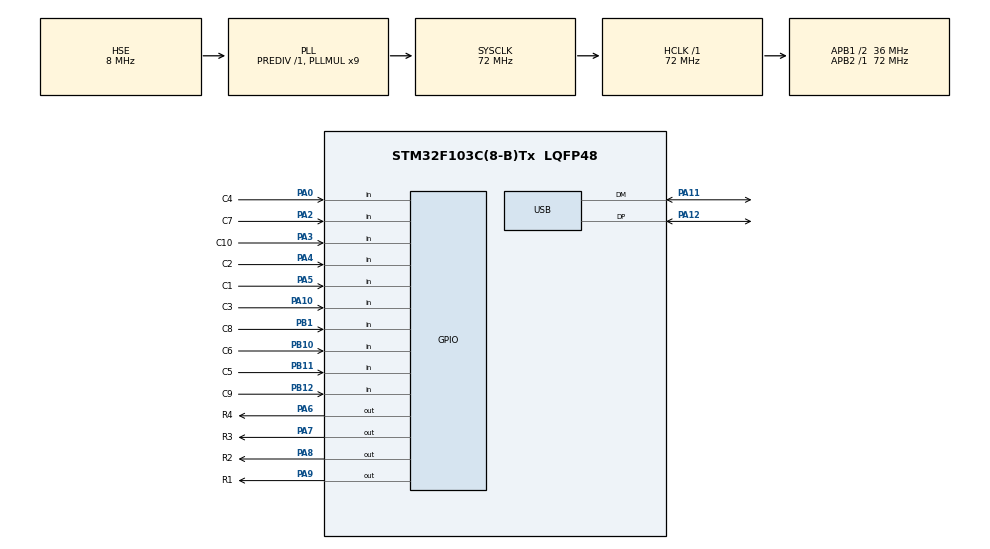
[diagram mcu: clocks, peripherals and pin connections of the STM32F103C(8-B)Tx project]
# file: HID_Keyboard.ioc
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Mcu.Family=STM32F1
Mcu.Name=STM32F103C(8-B)Tx
Mcu.Package=LQFP48
NVIC.PriorityGroup=NVIC_PRIORITYGROUP_4
NVIC.USB_LP_CAN1_RX0_IRQn=true\:0\:0\:false\:false\:true\:false\:true\:true
PA0-WKUP.GPIO_Label=C4
PA0-WKUP.GPIO_PuPd=GPIO_PULLUP
PA0-WKUP.Signal=GPIO_Input
PA10.GPIO_Label=C3
PA10.GPIO_PuPd=GPIO_PULLUP
PA10.Signal=GPIO_Input
PA11.Mode=Device
PA11.Signal=USB_DM
PA12.Mode=Device
PA12.Signal=USB_DP
PA2.GPIO_Label=C7
PA2.GPIO_PuPd=GPIO_PULLUP
PA2.Signal=GPIO_Input
PA3.GPIO_Label=C10
PA3.GPIO_PuPd=GPIO_PULLUP
PA3.Signal=GPIO_Input
PA4.GPIO_Label=C2
PA4.GPIO_PuPd=GPIO_PULLUP
PA4.Signal=GPIO_Input
PA5.GPIO_Label=C1
PA5.GPIO_PuPd=GPIO_PULLUP
PA5.Signal=GPIO_Input
PA6.GPIO_Label=R4
PA6.Signal=GPIO_Output
PA7.GPIO_Label=R3
PA7.Signal=GPIO_Output
PA8.GPIO_Label=R2
PA8.Signal=GPIO_Output
PA9.GPIO_Label=R1
PA9.Signal=GPIO_Output
PB1.GPIO_Label=C8
PB1.GPIO_PuPd=GPIO_PULLUP
PB1.Signal=GPIO_Input
PB10.GPIO_Label=C6
PB10.GPIO_PuPd=GPIO_PULLUP
PB10.Signal=GPIO_Input
PB11.GPIO_Label=C5
PB11.GPIO_PuPd=GPIO_PULLUP
PB11.Signal=GPIO_Input
PB12.GPIO_Label=C9
PB12.GPIO_PuPd=GPIO_PULLUP
PB12.Signal=GPIO_Input
PD0-OSC_IN.Mode=HSE-External-Oscillator
PD0-OSC_IN.Signal=RCC_OSC_IN
PD1-OSC_OUT.Mode=HSE-External-Oscillator
PD1-OSC_OUT.Signal=RCC_OSC_OUT
ProjectManager.HeapSize=0x200
ProjectManager.StackSize=0x400
ProjectManager.TargetToolchain=STM32CubeIDE
RCC.AHBFreq_Value=72000000
RCC.APB1CLKDivider=RCC_HCLK_DIV2
RCC.APB1Freq_Value=36000000
RCC.APB1TimFreq_Value=72000000
RCC.APB2Freq_Value=72000000
RCC.APB2TimFreq_Value=72000000
RCC.HCLKFreq_Value=72000000
RCC.PLLMUL=RCC_PLL_MUL9
RCC.PLLSourceVirtual=RCC_PLLSOURCE_HSE
RCC.SYSCLKFreq_VALUE=72000000
RCC.SYSCLKSource=RCC_SYSCLKSOURCE_PLLCLK
RCC.USBFreq_Value=48000000
RCC.USBPrescaler=RCC_USBCLKSOURCE_PLL_DIV1_5
USB_DEVICE.CLASS_NAME_FS=HID
USB_DEVICE.PRODUCT_STRING_HID_FS=ASKB
USB_DEVICE.VirtualMode=Hid
USB_DEVICE.VirtualModeFS=Hid_FS
VP_SYS_VS_ND.Mode=No_Debug
VP_USB_DEVICE_VS_USB_DEVICE_HID_FS.Mode=HID_FS
board=custom

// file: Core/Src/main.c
/* USER CODE BEGIN Header */
/**
  ******************************************************************************
  * @file           : main.c
  * @brief          : Main program body
  ******************************************************************************
  * @attention
  *
  * Copyright (c) 2024 STMicroelectronics.
  * All rights reserved.
  *
  * This software is licensed under terms that can be found in the LICENSE file
  * in the root directory of this software component.
  * If no LICENSE file comes with this software, it is provided AS-IS.
  *
  ******************************************************************************
  */
/* USER CODE END Header */
#include "main.h"
#include "usb_device.h"
#include "usb_hid_keys.h"

/* USER CODE BEGIN Includes */
#include "usbd_hid.h"
/* USER CODE END Includes */

/* USER CODE BEGIN PV */
extern USBD_HandleTypeDef hUsbDeviceFS;

/* USER CODE END PV */

void SystemClock_Config(void);
static void MX_GPIO_Init(void);

int main(void)
{

  /* MCU Configuration--------------------------------------------------------*/

  /* Reset of all peripherals, Initializes the Flash interface and the Systick. */
  HAL_Init();

  /* Configure the system clock */
  SystemClock_Config();

  /* Initialize all configured peripherals */
  MX_GPIO_Init();
  MX_USB_DEVICE_Init();

  /* USER CODE BEGIN 2 */
	//Esta estructura es para manejar mas facilmente los pines
  	typedef struct {
  		uint16_t Pin;
  		GPIO_TypeDef* GPIO_Port;
	} stm32GPIO;

	//Estructura del reporte que se envia por protocolo HID a la computadora
  	typedef struct {
	    uint8_t MODIFIER;
      	uint8_t RESERVED;
      	uint8_t KEYCODE01;
      	uint8_t KEYCODE02;
      	uint8_t KEYCODE03;
      	uint8_t KEYCODE04;
      	uint8_t KEYCODE05;
      	uint8_t KEYCODE06;
	} keyboardReportsDes;

	//Inicializacion de la esttructura con los pins de las filas
	stm32GPIO GPIORows[4] = {
		{R1_Pin, R1_GPIO_Port},
		{R2_Pin, R2_GPIO_Port},
		{R3_Pin, R3_GPIO_Port},
		{R4_Pin, R4_GPIO_Port}
	};

	//Inicializacion de la esttructura con los pins de las columnas
	stm32GPIO GPIOCols[10] = {
		{C1_Pin, C1_GPIO_Port},
		{C2_Pin, C2_GPIO_Port},
		{C3_Pin, C3_GPIO_Port},
		{C4_Pin, C4_GPIO_Port},
		{C5_Pin, C5_GPIO_Port},
		{C6_Pin, C6_GPIO_Port},
		{C7_Pin, C7_GPIO_Port},
		{C8_Pin, C8_GPIO_Port},
		{C9_Pin, C9_GPIO_Port},
		{C10_Pin, C10_GPIO_Port}
	};

	//Inicializacion de la estructura con los pins repetidos para las estructuras de control
	stm32GPIO GPIOControl[3] = {
		{C8_Pin, C8_GPIO_Port},
		{C5_Pin, C5_GPIO_Port},
		{C7_Pin, C7_GPIO_Port}
	};

	uint8_t keyMatrix[5][10][3] =
		{
			{
				{
					Q,K1,F1
				},
				{
					W,K2,F2
				},
				{
					E,K3,F3
				},
				{
					R,K4,F4
				},
				{
					T,K5,VUP
				},
				{
					Y,K6,PREV
				},
				{
					U,K7,PLAY
				},
				{
					I,K8,NEXT
				},
				{
					O,K9,STOP
				},
				{
					P,K0,PRINT
				}
			},
			{
				{
					A,ESC,F5
				},
				{
					S,0,F6
				},
				{
					D,0,F7
				},
				{
					F,0,F8
				},
				{
					G,0,VDN
				},
				{
					H,LCORCH,FIZ
				},
				{
					J,RCORCH,FAB
				},
				{
					K,BSLASH,FAR
				},
				{
					L,GUION,FDE
				},
				{
					PYCOMA,IGUAL,BLOCKM
				}
			},
			{
				{
					Z,PUP,F9
				},
				{
					X,PDN,F10
				},
				{
					C,HOME,F11
				},
				{
					V,END,F12
				},
				{
					B,0,MUTE
				},
				{
					ENTER,ENTER,ENTER
				},
				{
					N,APPMENU,0
				},
				{
					M,BCOMILL,0
				},
				{
					COMA,COMILLA,0
				},
				{
					PUNTO,TAB,0x00
				}
			},
			{
				{
					0,0,0
				},
				{
					0,0,0
				},
				{
					0,0,0
				},
				{
					SPACE,SPACE,SPACE
				},
				{
					0,0,0
				},
				{
					0,0,0
				},
				{
					0,0,0
				},
				{
					0,0,0
				},
				{
					0,0,0
				},
				{
					SLASH,BACKS,DELETE
				}
			},
			{
				{
					SHIFT,SHIFT,SHIFT
				},
				{
					CTRL,CTRL,CTRL
				},
				{
					ALT,GUI,ALT
				},
			}
		};

	//Inicializacion de la estructura para el reporte HID
	keyboardReportsDes HIDKeyboard = {0,0,0,0,0,0,0,0};

	//Short que se utiliza para definir en que capa del teclado estamos parados
	short control = 0;

	//While loop que se ejecuta durante todo el funcionamiento del equipo
	while (1)
	{
		//Este es el puntero que utilizo para cargar los codigos dentro de la estructura de reporte de manera secuencial
		//solo se usa ara los KEYCODE*, los primeros dos bytes se manejan de manera distinta.
		uint8_t *ptr_key = &HIDKeyboard.KEYCODE01;

		//Coloco los pines en la posicion de inicio
		for(int i = 0 ; i < 4; i++)
		{
				HAL_GPIO_WritePin(GPIORows[i].GPIO_Port, GPIORows[i].Pin, GPIO_PIN_SET);
		}
		HAL_GPIO_WritePin(GPIORows[3].GPIO_Port, GPIORows[3].Pin, GPIO_PIN_RESET);

		//Defino la capa donde se esta trabajando segun los dos botones internos que no modifican directametne
		//el reporte de teclad (fnL y fnR)
		if(!(HAL_GPIO_ReadPin(C3_GPIO_Port, C3_Pin))){
			control = C1;
		}

		if (!(HAL_GPIO_ReadPin(C9_GPIO_Port, C9_Pin))){
			control = C2;
		}

		//Compruebo que botones estan siendo pulsados paca configurar los modificadores y las capas de teclado
		for(int i = 0; i < 3; i++)
		{
			if(!(HAL_GPIO_ReadPin(GPIOControl[i].GPIO_Port, GPIOControl[i].Pin)))
			{
				HIDKeyboard.MODIFIER = keyMatrix[4][i][control] + HIDKeyboard.MODIFIER;
			}
		}

		//for que recorre las filas
		for(int i = 0; i < 4; i++)
		{
			//Este segundo loop anidado se encarga de apagar la corriente de todos los pines que no se tengan que
			//leer durante este ciclo.
			for(int j = 0; j < 4; j++)
			{
				if(j == i)
				{
					HAL_GPIO_WritePin(GPIORows[j].GPIO_Port, GPIORows[j].Pin, GPIO_PIN_RESET);
				}
				else
				{
					HAL_GPIO_WritePin(GPIORows[j].GPIO_Port, GPIORows[j].Pin, GPIO_PIN_SET);
				}
			}

			//Ahora se realiza un segundo loop que se encarga de recorrer cada una de las columnas,
			//este se corre 10 veces por cada fila. Aparte, si se carga un byte dentro de la estructura
			//de reporte, mueve el puntero adelante hasta llegar al ultimo espacio de memoria, en ese caso
			//vuelve al principio
			for(int h = 0; h < 10; h++)
			{
				if(!(HAL_GPIO_ReadPin(GPIOCols[h].GPIO_Port, GPIOCols[h].Pin)))
				{
					*ptr_key = keyMatrix[i][h][control];

					if(keyMatrix[i][h][control] != 0x00)
					{
						if(ptr_key != &HIDKeyboard.KEYCODE06)
						{
							ptr_key++;
						}
						else
						{
							ptr_key = &HIDKeyboard.KEYCODE01;
						}
					}
				}
			}
		}

		//Envio el reporte por USB
		USBD_HID_SendReport(&hUsbDeviceFS,&HIDKeyboard,sizeof(HIDKeyboard));
		//Espero para que no se pisen los reportes dentro del cable
		HAL_Delay(25);
		//Limpio todas las variabes necesarias antes de que vuelva a arrancar el loop
		//principal de la aplicacion.
		HIDKeyboard.MODIFIER  = 0x00;
		HIDKeyboard.RESERVED  = 0x00;
		HIDKeyboard.KEYCODE01 = 0x00;
		HIDKeyboard.KEYCODE02 = 0x00;
		HIDKeyboard.KEYCODE03 = 0x00;
		HIDKeyboard.KEYCODE04 = 0x00;
		HIDKeyboard.KEYCODE05 = 0x00;
		HIDKeyboard.KEYCODE06 = 0x00;
		control = 0;

      /* USER CODE END 3 */

    /* USER CODE END 3 */
    }
}

void SystemClock_Config(void)
{
  RCC_OscInitTypeDef RCC_OscInitStruct = {0};
  RCC_ClkInitTypeDef RCC_ClkInitStruct = {0};
  RCC_PeriphCLKInitTypeDef PeriphClkInit = {0};

  /** Initializes the RCC Oscillators according to the specified parameters
  * in the RCC_OscInitTypeDef structure.
  */
  RCC_OscInitStruct.OscillatorType = RCC_OSCILLATORTYPE_HSE;
  RCC_OscInitStruct.HSEState = RCC_HSE_ON;
  RCC_OscInitStruct.HSEPredivValue = RCC_HSE_PREDIV_DIV1;
  RCC_OscInitStruct.HSIState = RCC_HSI_ON;
  RCC_OscInitStruct.PLL.PLLState = RCC_PLL_ON;
  RCC_OscInitStruct.PLL.PLLSource = RCC_PLLSOURCE_HSE;
  RCC_OscInitStruct.PLL.PLLMUL = RCC_PLL_MUL9;
  if (HAL_RCC_OscConfig(&RCC_OscInitStruct) != HAL_OK)
  {
    Error_Handler();
  }

  /** Initializes the CPU, AHB and APB buses clocks
  */
  RCC_ClkInitStruct.ClockType = RCC_CLOCKTYPE_HCLK|RCC_CLOCKTYPE_SYSCLK
                              |RCC_CLOCKTYPE_PCLK1|RCC_CLOCKTYPE_PCLK2;
  RCC_ClkInitStruct.SYSCLKSource = RCC_SYSCLKSOURCE_PLLCLK;
  RCC_ClkInitStruct.AHBCLKDivider = RCC_SYSCLK_DIV1;
  RCC_ClkInitStruct.APB1CLKDivider = RCC_HCLK_DIV2;
  RCC_ClkInitStruct.APB2CLKDivider = RCC_HCLK_DIV1;

  if (HAL_RCC_ClockConfig(&RCC_ClkInitStruct, FLASH_LATENCY_2) != HAL_OK)
  {
    Error_Handler();
  }
  PeriphClkInit.PeriphClockSelection = RCC_PERIPHCLK_USB;
  PeriphClkInit.UsbClockSelection = RCC_USBCLKSOURCE_PLL_DIV1_5;
  if (HAL_RCCEx_PeriphCLKConfig(&PeriphClkInit) != HAL_OK)
  {
    Error_Handler();
  }
}

static void MX_GPIO_Init(void)
{
  GPIO_InitTypeDef GPIO_InitStruct = {0};

  /* GPIO Ports Clock Enable */
  __HAL_RCC_GPIOD_CLK_ENABLE();
  __HAL_RCC_GPIOA_CLK_ENABLE();
  __HAL_RCC_GPIOB_CLK_ENABLE();

  /*Configure GPIO pin Output Level */
  HAL_GPIO_WritePin(GPIOA, R4_Pin|R3_Pin|R2_Pin|R1_Pin, GPIO_PIN_RESET);

  /*Configure GPIO pins : C4_Pin C7_Pin C10_Pin C2_Pin
                           C1_Pin C3_Pin */
  GPIO_InitStruct.Pin = C4_Pin|C7_Pin|C10_Pin|C2_Pin
                          |C1_Pin|C3_Pin;
  GPIO_InitStruct.Mode = GPIO_MODE_INPUT;
  GPIO_InitStruct.Pull = GPIO_PULLUP;
  HAL_GPIO_Init(GPIOA, &GPIO_InitStruct);

  /*Configure GPIO pins : R4_Pin R3_Pin R2_Pin R1_Pin */
  GPIO_InitStruct.Pin = R4_Pin|R3_Pin|R2_Pin|R1_Pin;
  GPIO_InitStruct.Mode = GPIO_MODE_OUTPUT_PP;
  GPIO_InitStruct.Pull = GPIO_NOPULL;
  GPIO_InitStruct.Speed = GPIO_SPEED_FREQ_LOW;
  HAL_GPIO_Init(GPIOA, &GPIO_InitStruct);

  /*Configure GPIO pins : C8_Pin C6_Pin C5_Pin C9_Pin */
  GPIO_InitStruct.Pin = C8_Pin|C6_Pin|C5_Pin|C9_Pin;
  GPIO_InitStruct.Mode = GPIO_MODE_INPUT;
  GPIO_InitStruct.Pull = GPIO_PULLUP;
  HAL_GPIO_Init(GPIOB, &GPIO_InitStruct);

}

void Error_Handler(void)
{
  __disable_irq();
  while (1)
  {
  }
}
